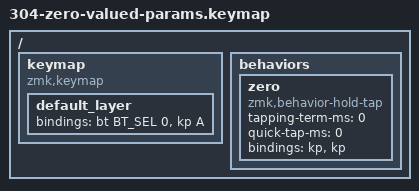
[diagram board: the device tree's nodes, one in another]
/* Synthesized from issue #304: the discussion confirms zero is a valid timing value but includes no source excerpt. */
/ {
    keymap {
        compatible = "zmk,keymap";
        default_layer { bindings = <&bt BT_SEL 0 &kp A>; };
    };
    behaviors {
        zero: zero { compatible = "zmk,behavior-hold-tap"; #binding-cells = <2>; tapping-term-ms = <0>; quick-tap-ms = <0>; bindings = <&kp>, <&kp>; };
    };

};
